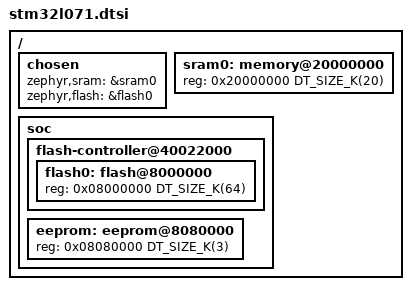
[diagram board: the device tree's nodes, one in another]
/*
 * Copyright (c) 2020 Barak Gutman <barak381@gmail.com>
 *
 * SPDX-License-Identifier: Apache-2.0
 */

#include <mem.h>
#include <st/l0/stm32l0.dtsi>

/ {
	chosen {
		zephyr,sram = &sram0;
		zephyr,flash = &flash0;
	};

	sram0: memory@20000000 {
		reg = <0x20000000 DT_SIZE_K(20)>;
	};

	soc {
		flash-controller@40022000 {
			flash0: flash@8000000 {
				reg = <0x08000000 DT_SIZE_K(64)>;
			};
		};

		eeprom: eeprom@8080000{
			reg = <0x08080000 DT_SIZE_K(3)>;
		};
	};
};
